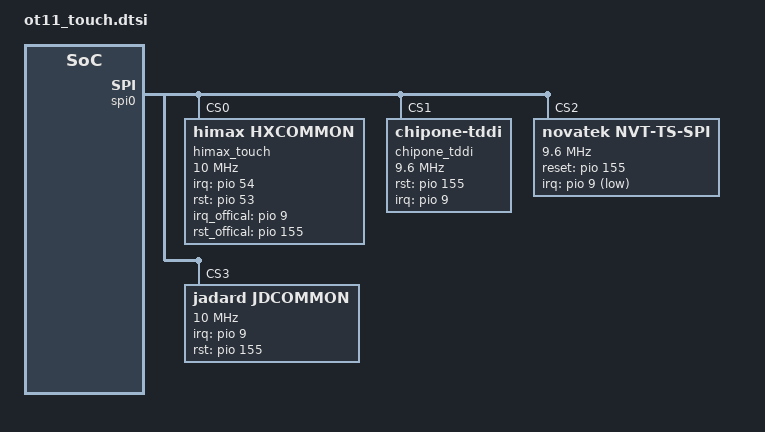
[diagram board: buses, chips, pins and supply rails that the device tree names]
// SPDX-License-Identifier: (GPL-2.0 OR MIT)
/*
 * Copyright (C) 2020 MediaTek Inc.
 */

/* TOUCH start */
&spi0 {
    status = "okay";
    #address-cells = <1>;
    #size-cells = <0>;
    mediatek,pad-select = <0>;
    /*Tab A9 code for AX6739W-7 by xiongwei at 20250812 start*/
    cs-gpios = <0>, <0>, <0>, <0>;
    /*Tab A9 code for AX6739W-7 by xiongwei at 20250812 end*/

    himax_touch@0 {
        compatible = "himax,hxcommon";
        reg = <0>;
        status = "okay";
        spi-max-frequency = <10000000>;
        spi-cpha;
        interrupt-parent = <&pio>;
        himax,panel-coords = <0 800 0 1340>;
        himax,display-coords = <0 800 0 1340>;
        himax,irq-gpio = <&pio 54 0x00>;
	/*Tab A9 code for AX6739W-46 by xiongwei at 20250827 start*/
        himax,rst-gpio = <&pio 53 0x00>;
	/*Tab A9 code for AX6739W-46 by xiongwei at 20250827 end*/

        himax,irq_offical-gpio = <&pio 9 0x00>;
        himax,rst_offical-gpio = <&pio 155 0x00>;
        report_type = <1>;
    };
    chipone_tddi@1 {
        compatible = "chipone-tddi";
        reg = <1>;
        spi-max-frequency = <9600000>;
        interrupt-parent = <&pio>;
        interrupts = <9 0x2008>;
        chipone,rst-gpio = <&pio 155 0x00>;
        chipone,irq-gpio = <&pio 9 0x00>;
        //chipone,cs-gpio = <&pio 8 0>;
        chipone,x-res = <800>;
        chipone,y-res = <1340>;

        /* Charger detect */
        chipone,touch-charger-detect-enable;
        chipone,touch-charger-detect-type = "notify"; /* notify, poll */
        chipone,touch-charger-detect-psy-name = "charger";
        chipone,touch-charger-detect-psp = "POWER_SUPPLY_PROP_ONLINE";
        chipone,touch-charger-detect-psp-poll-interval = <1000>;

        /* Earjack detect */
        chipone,touch-earjack-detect-enable;
        /* MTK:  /sys/bus/platform/drivers/Accdet_Driver/state,
           Sprd: /sys/kernel/headset/state
           QCOM: None, and disable it */
        chipone,touch-earjack-state-filepath = "/sys/bus/platform/drivers/Accdet_Driver/state";
        chipone,touch-earjack-poll-interval = <1000>;

        /* For tp selftest */
        chipone,test-reset-pin;
        //chipone,test-int-pin;
        chipone,test-rawdata;
        chipone,test-rawdata-frames      = <1>;
        chipone,rawdata-min              = <100>;
        chipone,rawdata-max              = <10000>;
        chipone,test-noise;
        chipone,test-noise-frames        = <50>;
        chipone,noise-max                = <1000>;
        chipone,test-open;
        chipone,open-min                 = <200>;
        chipone,test-short;
        chipone,short-min                = <200>;
        chipone,test-compensate-cap;
        chipone,compensate-cap-min       = <1>;
        chipone,compensate-cap-max       = <127>;

    };
    /* Novatek device tree node */
    novatek@2 {
        compatible = "novatek,NVT-ts-spi";
        reg = <2>; //Same as CS ID
        status = "ok";

        spi-max-frequency = <9600000>;    //4800000,9600000,15000000,19200000
        novatek,reset-gpio = <&pio 155 0x00>;
        novatek,irq-gpio = <&pio 9 0x2001>;

        /* 525 */
        //novatek,swrst-n8-addr = <0x01F01A>;

        /* 672A, 525B, 675, 526, 672C, 523, 528, 523D */
        novatek,swrst-n8-addr = <0x03F0FE>;
        novatek,spi-rd-fast-addr = <0x03F310>;

        /*Panel setting*/
        novatek,resolution = <800 1340>;
        novatek,max_touch_num = <10>;
        novatek,area-size = <56 112 60>;    //indicator navigation edge
        novatek,fw_name = "novatek_ts_fw.bin", "tsp_novatek/OT11_NT36523D_LC_HSD_FW_V001_2023xxxx.bin";
        novatek,fw_name_mp = "novatek_ts_mp.bin", "tsp_novatek/OT11_NT36523D_LC_HSD_MP_V001_2023xxxx.bin ";
        //novatek,support_ear_detect_mode;
        novatek,enable_settings_aot;

        /* MP */
        novatek,mp-support-dt;

        novatek-mp-criteria-725E@0 {
            #address-cells = <1>;
            #size-cells = <0>;
            compatible = "novatek-mp-criteria-725E";

            /* sec cmd test config */
            open_test_spec = <(-511) 5120>;
            short_test_spec = <10000 14008>;
            diff_test_frame = <50>;
            /* sec cmd fdm test config */
            fdm_x_num = <2>;
            fdm_diff_test_frame = <50>;

            /* MP Config */
            IC_X_CFG_SIZE = <22>;
            IC_Y_CFG_SIZE = <36>;
            IC_KEY_CFG_SIZE = <4>;
            X_Channel = <22>;
            Y_Channel = <36>;
            AIN_X = <0 1 2 3 4 5 6 7 8 9 10 11 12 13 14 15 16 17 18 19 20 21>; // 22 23 24 25 26 27 28 29 30 31>;
            AIN_Y = <0 1 2 3 4 5 6 7 8 9 10 11 12 13 14 15 16 17
                        18 19 20 21 22 23 24 25 26 27 28 29 30 31 32 33 34 35>; // 36 37 38 39
                        //40 41 42 43 44 45 46 47 48 49>;
            AIN_KEY = <0 1 2 0xFF 0xFF 0xFF 0xFF 0xFF>;

            /* MP Criteria */
            PS_Config_Lmt_Short_Rawdata_P = <
                14008 14008 14008 14008 14008 14008 14008 14008 14008 14008 14008 14008 14008 14008 14008 14008 14008 14008 14008 14008 14008 14008
                14008 14008 14008 14008 14008 14008 14008 14008 14008 14008 14008 14008 14008 14008 14008 14008 14008 14008 14008 14008 14008 14008
                14008 14008 14008 14008 14008 14008 14008 14008 14008 14008 14008 14008 14008 14008 14008 14008 14008 14008 14008 14008 14008 14008
                14008 14008 14008 14008 14008 14008 14008 14008 14008 14008 14008 14008 14008 14008 14008 14008 14008 14008 14008 14008 14008 14008
                14008 14008 14008 14008 14008 14008 14008 14008 14008 14008 14008 14008 14008 14008 14008 14008 14008 14008 14008 14008 14008 14008
                14008 14008 14008 14008 14008 14008 14008 14008 14008 14008 14008 14008 14008 14008 14008 14008 14008 14008 14008 14008 14008 14008
                14008 14008 14008 14008 14008 14008 14008 14008 14008 14008 14008 14008 14008 14008 14008 14008 14008 14008 14008 14008 14008 14008
                14008 14008 14008 14008 14008 14008 14008 14008 14008 14008 14008 14008 14008 14008 14008 14008 14008 14008 14008 14008 14008 14008
                14008 14008 14008 14008 14008 14008 14008 14008 14008 14008 14008 14008 14008 14008 14008 14008 14008 14008 14008 14008 14008 14008
                14008 14008 14008 14008 14008 14008 14008 14008 14008 14008 14008 14008 14008 14008 14008 14008 14008 14008 14008 14008 14008 14008
                14008 14008 14008 14008 14008 14008 14008 14008 14008 14008 14008 14008 14008 14008 14008 14008 14008 14008 14008 14008 14008 14008
                14008 14008 14008 14008 14008 14008 14008 14008 14008 14008 14008 14008 14008 14008 14008 14008 14008 14008 14008 14008 14008 14008
                14008 14008 14008 14008 14008 14008 14008 14008 14008 14008 14008 14008 14008 14008 14008 14008 14008 14008 14008 14008 14008 14008
                14008 14008 14008 14008 14008 14008 14008 14008 14008 14008 14008 14008 14008 14008 14008 14008 14008 14008 14008 14008 14008 14008
                14008 14008 14008 14008 14008 14008 14008 14008 14008 14008 14008 14008 14008 14008 14008 14008 14008 14008 14008 14008 14008 14008
                14008 14008 14008 14008 14008 14008 14008 14008 14008 14008 14008 14008 14008 14008 14008 14008 14008 14008 14008 14008 14008 14008
                14008 14008 14008 14008 14008 14008 14008 14008 14008 14008 14008 14008 14008 14008 14008 14008 14008 14008 14008 14008 14008 14008
                14008 14008 14008 14008 14008 14008 14008 14008 14008 14008 14008 14008 14008 14008 14008 14008 14008 14008 14008 14008 14008 14008
                14008 14008 14008 14008 14008 14008 14008 14008 14008 14008 14008 14008 14008 14008 14008 14008 14008 14008 14008 14008 14008 14008
                14008 14008 14008 14008 14008 14008 14008 14008 14008 14008 14008 14008 14008 14008 14008 14008 14008 14008 14008 14008 14008 14008
                14008 14008 14008 14008 14008 14008 14008 14008 14008 14008 14008 14008 14008 14008 14008 14008 14008 14008 14008 14008 14008 14008
                14008 14008 14008 14008 14008 14008 14008 14008 14008 14008 14008 14008 14008 14008 14008 14008 14008 14008 14008 14008 14008 14008
                14008 14008 14008 14008 14008 14008 14008 14008 14008 14008 14008 14008 14008 14008 14008 14008 14008 14008 14008 14008 14008 14008
                14008 14008 14008 14008 14008 14008 14008 14008 14008 14008 14008 14008 14008 14008 14008 14008 14008 14008 14008 14008 14008 14008
                14008 14008 14008 14008 14008 14008 14008 14008 14008 14008 14008 14008 14008 14008 14008 14008 14008 14008 14008 14008 14008 14008
                14008 14008 14008 14008 14008 14008 14008 14008 14008 14008 14008 14008 14008 14008 14008 14008 14008 14008 14008 14008 14008 14008
                14008 14008 14008 14008 14008 14008 14008 14008 14008 14008 14008 14008 14008 14008 14008 14008 14008 14008 14008 14008 14008 14008
                14008 14008 14008 14008 14008 14008 14008 14008 14008 14008 14008 14008 14008 14008 14008 14008 14008 14008 14008 14008 14008 14008
                14008 14008 14008 14008 14008 14008 14008 14008 14008 14008 14008 14008 14008 14008 14008 14008 14008 14008 14008 14008 14008 14008
                14008 14008 14008 14008 14008 14008 14008 14008 14008 14008 14008 14008 14008 14008 14008 14008 14008 14008 14008 14008 14008 14008
                14008 14008 14008 14008 14008 14008 14008 14008 14008 14008 14008 14008 14008 14008 14008 14008 14008 14008 14008 14008 14008 14008
                14008 14008 14008 14008 14008 14008 14008 14008 14008 14008 14008 14008 14008 14008 14008 14008 14008 14008 14008 14008 14008 14008
                14008 14008 14008 14008 14008 14008 14008 14008 14008 14008 14008 14008 14008 14008 14008 14008 14008 14008 14008 14008 14008 14008
                14008 14008 14008 14008 14008 14008 14008 14008 14008 14008 14008 14008 14008 14008 14008 14008 14008 14008 14008 14008 14008 14008
                14008 14008 14008 14008 14008 14008 14008 14008 14008 14008 14008 14008 14008 14008 14008 14008 14008 14008 14008 14008 14008 14008
                14008 14008 14008 14008 14008 14008 14008 14008 14008 14008 14008 14008 14008 14008 14008 14008 14008 14008 14008 14008 14008 14008
                14008 14008 14008>;

            PS_Config_Lmt_Short_Rawdata_N = <
                10000 10000 10000 10000 10000 10000 10000 10000 10000 10000 10000 10000 10000 10000 10000 10000 10000 10000 10000 10000 10000 10000
                10000 10000 10000 10000 10000 10000 10000 10000 10000 10000 10000 10000 10000 10000 10000 10000 10000 10000 10000 10000 10000 10000
                10000 10000 10000 10000 10000 10000 10000 10000 10000 10000 10000 10000 10000 10000 10000 10000 10000 10000 10000 10000 10000 10000
                10000 10000 10000 10000 10000 10000 10000 10000 10000 10000 10000 10000 10000 10000 10000 10000 10000 10000 10000 10000 10000 10000
                10000 10000 10000 10000 10000 10000 10000 10000 10000 10000 10000 10000 10000 10000 10000 10000 10000 10000 10000 10000 10000 10000
                10000 10000 10000 10000 10000 10000 10000 10000 10000 10000 10000 10000 10000 10000 10000 10000 10000 10000 10000 10000 10000 10000
                10000 10000 10000 10000 10000 10000 10000 10000 10000 10000 10000 10000 10000 10000 10000 10000 10000 10000 10000 10000 10000 10000
                10000 10000 10000 10000 10000 10000 10000 10000 10000 10000 10000 10000 10000 10000 10000 10000 10000 10000 10000 10000 10000 10000
                10000 10000 10000 10000 10000 10000 10000 10000 10000 10000 10000 10000 10000 10000 10000 10000 10000 10000 10000 10000 10000 10000
                10000 10000 10000 10000 10000 10000 10000 10000 10000 10000 10000 10000 10000 10000 10000 10000 10000 10000 10000 10000 10000 10000
                10000 10000 10000 10000 10000 10000 10000 10000 10000 10000 10000 10000 10000 10000 10000 10000 10000 10000 10000 10000 10000 10000
                10000 10000 10000 10000 10000 10000 10000 10000 10000 10000 10000 10000 10000 10000 10000 10000 10000 10000 10000 10000 10000 10000
                10000 10000 10000 10000 10000 10000 10000 10000 10000 10000 10000 10000 10000 10000 10000 10000 10000 10000 10000 10000 10000 10000
                10000 10000 10000 10000 10000 10000 10000 10000 10000 10000 10000 10000 10000 10000 10000 10000 10000 10000 10000 10000 10000 10000
                10000 10000 10000 10000 10000 10000 10000 10000 10000 10000 10000 10000 10000 10000 10000 10000 10000 10000 10000 10000 10000 10000
                10000 10000 10000 10000 10000 10000 10000 10000 10000 10000 10000 10000 10000 10000 10000 10000 10000 10000 10000 10000 10000 10000
                10000 10000 10000 10000 10000 10000 10000 10000 10000 10000 10000 10000 10000 10000 10000 10000 10000 10000 10000 10000 10000 10000
                10000 10000 10000 10000 10000 10000 10000 10000 10000 10000 10000 10000 10000 10000 10000 10000 10000 10000 10000 10000 10000 10000
                10000 10000 10000 10000 10000 10000 10000 10000 10000 10000 10000 10000 10000 10000 10000 10000 10000 10000 10000 10000 10000 10000
                10000 10000 10000 10000 10000 10000 10000 10000 10000 10000 10000 10000 10000 10000 10000 10000 10000 10000 10000 10000 10000 10000
                10000 10000 10000 10000 10000 10000 10000 10000 10000 10000 10000 10000 10000 10000 10000 10000 10000 10000 10000 10000 10000 10000
                10000 10000 10000 10000 10000 10000 10000 10000 10000 10000 10000 10000 10000 10000 10000 10000 10000 10000 10000 10000 10000 10000
                10000 10000 10000 10000 10000 10000 10000 10000 10000 10000 10000 10000 10000 10000 10000 10000 10000 10000 10000 10000 10000 10000
                10000 10000 10000 10000 10000 10000 10000 10000 10000 10000 10000 10000 10000 10000 10000 10000 10000 10000 10000 10000 10000 10000
                10000 10000 10000 10000 10000 10000 10000 10000 10000 10000 10000 10000 10000 10000 10000 10000 10000 10000 10000 10000 10000 10000
                10000 10000 10000 10000 10000 10000 10000 10000 10000 10000 10000 10000 10000 10000 10000 10000 10000 10000 10000 10000 10000 10000
                10000 10000 10000 10000 10000 10000 10000 10000 10000 10000 10000 10000 10000 10000 10000 10000 10000 10000 10000 10000 10000 10000
                10000 10000 10000 10000 10000 10000 10000 10000 10000 10000 10000 10000 10000 10000 10000 10000 10000 10000 10000 10000 10000 10000
                10000 10000 10000 10000 10000 10000 10000 10000 10000 10000 10000 10000 10000 10000 10000 10000 10000 10000 10000 10000 10000 10000
                10000 10000 10000 10000 10000 10000 10000 10000 10000 10000 10000 10000 10000 10000 10000 10000 10000 10000 10000 10000 10000 10000
                10000 10000 10000 10000 10000 10000 10000 10000 10000 10000 10000 10000 10000 10000 10000 10000 10000 10000 10000 10000 10000 10000
                10000 10000 10000 10000 10000 10000 10000 10000 10000 10000 10000 10000 10000 10000 10000 10000 10000 10000 10000 10000 10000 10000
                10000 10000 10000 10000 10000 10000 10000 10000 10000 10000 10000 10000 10000 10000 10000 10000 10000 10000 10000 10000 10000 10000
                10000 10000 10000 10000 10000 10000 10000 10000 10000 10000 10000 10000 10000 10000 10000 10000 10000 10000 10000 10000 10000 10000
                10000 10000 10000 10000 10000 10000 10000 10000 10000 10000 10000 10000 10000 10000 10000 10000 10000 10000 10000 10000 10000 10000
                10000 10000 10000 10000 10000 10000 10000 10000 10000 10000 10000 10000 10000 10000 10000 10000 10000 10000 10000 10000 10000 10000
                10000 10000 10000>;

            PS_Config_Lmt_Open_Rawdata_P = <
                5120 5120 5120 5120 5120 5120 5120 5120 5120 5120 5120 5120 5120 5120 5120 5120 5120 5120 5120 5120 5120 5120
                5120 5120 5120 5120 5120 5120 5120 5120 5120 5120 5120 5120 5120 5120 5120 5120 5120 5120 5120 5120 5120 5120
                5120 5120 5120 5120 5120 5120 5120 5120 5120 5120 5120 5120 5120 5120 5120 5120 5120 5120 5120 5120 5120 5120
                5120 5120 5120 5120 5120 5120 5120 5120 5120 5120 5120 5120 5120 5120 5120 5120 5120 5120 5120 5120 5120 5120
                5120 5120 5120 5120 5120 5120 5120 5120 5120 5120 5120 5120 5120 5120 5120 5120 5120 5120 5120 5120 5120 5120
                5120 5120 5120 5120 5120 5120 5120 5120 5120 5120 5120 5120 5120 5120 5120 5120 5120 5120 5120 5120 5120 5120
                5120 5120 5120 5120 5120 5120 5120 5120 5120 5120 5120 5120 5120 5120 5120 5120 5120 5120 5120 5120 5120 5120
                5120 5120 5120 5120 5120 5120 5120 5120 5120 5120 5120 5120 5120 5120 5120 5120 5120 5120 5120 5120 5120 5120
                5120 5120 5120 5120 5120 5120 5120 5120 5120 5120 5120 5120 5120 5120 5120 5120 5120 5120 5120 5120 5120 5120
                5120 5120 5120 5120 5120 5120 5120 5120 5120 5120 5120 5120 5120 5120 5120 5120 5120 5120 5120 5120 5120 5120
                5120 5120 5120 5120 5120 5120 5120 5120 5120 5120 5120 5120 5120 5120 5120 5120 5120 5120 5120 5120 5120 5120
                5120 5120 5120 5120 5120 5120 5120 5120 5120 5120 5120 5120 5120 5120 5120 5120 5120 5120 5120 5120 5120 5120
                5120 5120 5120 5120 5120 5120 5120 5120 5120 5120 5120 5120 5120 5120 5120 5120 5120 5120 5120 5120 5120 5120
                5120 5120 5120 5120 5120 5120 5120 5120 5120 5120 5120 5120 5120 5120 5120 5120 5120 5120 5120 5120 5120 5120
                5120 5120 5120 5120 5120 5120 5120 5120 5120 5120 5120 5120 5120 5120 5120 5120 5120 5120 5120 5120 5120 5120
                5120 5120 5120 5120 5120 5120 5120 5120 5120 5120 5120 5120 5120 5120 5120 5120 5120 5120 5120 5120 5120 5120
                5120 5120 5120 5120 5120 5120 5120 5120 5120 5120 5120 5120 5120 5120 5120 5120 5120 5120 5120 5120 5120 5120
                5120 5120 5120 5120 5120 5120 5120 5120 5120 5120 5120 5120 5120 5120 5120 5120 5120 5120 5120 5120 5120 5120
                5120 5120 5120 5120 5120 5120 5120 5120 5120 5120 5120 5120 5120 5120 5120 5120 5120 5120 5120 5120 5120 5120
                5120 5120 5120 5120 5120 5120 5120 5120 5120 5120 5120 5120 5120 5120 5120 5120 5120 5120 5120 5120 5120 5120
                5120 5120 5120 5120 5120 5120 5120 5120 5120 5120 5120 5120 5120 5120 5120 5120 5120 5120 5120 5120 5120 5120
                5120 5120 5120 5120 5120 5120 5120 5120 5120 5120 5120 5120 5120 5120 5120 5120 5120 5120 5120 5120 5120 5120
                5120 5120 5120 5120 5120 5120 5120 5120 5120 5120 5120 5120 5120 5120 5120 5120 5120 5120 5120 5120 5120 5120
                5120 5120 5120 5120 5120 5120 5120 5120 5120 5120 5120 5120 5120 5120 5120 5120 5120 5120 5120 5120 5120 5120
                5120 5120 5120 5120 5120 5120 5120 5120 5120 5120 5120 5120 5120 5120 5120 5120 5120 5120 5120 5120 5120 5120
                5120 5120 5120 5120 5120 5120 5120 5120 5120 5120 5120 5120 5120 5120 5120 5120 5120 5120 5120 5120 5120 5120
                5120 5120 5120 5120 5120 5120 5120 5120 5120 5120 5120 5120 5120 5120 5120 5120 5120 5120 5120 5120 5120 5120
                5120 5120 5120 5120 5120 5120 5120 5120 5120 5120 5120 5120 5120 5120 5120 5120 5120 5120 5120 5120 5120 5120
                5120 5120 5120 5120 5120 5120 5120 5120 5120 5120 5120 5120 5120 5120 5120 5120 5120 5120 5120 5120 5120 5120
                5120 5120 5120 5120 5120 5120 5120 5120 5120 5120 5120 5120 5120 5120 5120 5120 5120 5120 5120 5120 5120 5120
                5120 5120 5120 5120 5120 5120 5120 5120 5120 5120 5120 5120 5120 5120 5120 5120 5120 5120 5120 5120 5120 5120
                5120 5120 5120 5120 5120 5120 5120 5120 5120 5120 5120 5120 5120 5120 5120 5120 5120 5120 5120 5120 5120 5120
                5120 5120 5120 5120 5120 5120 5120 5120 5120 5120 5120 5120 5120 5120 5120 5120 5120 5120 5120 5120 5120 5120
                5120 5120 5120 5120 5120 5120 5120 5120 5120 5120 5120 5120 5120 5120 5120 5120 5120 5120 5120 5120 5120 5120
                5120 5120 5120 5120 5120 5120 5120 5120 5120 5120 5120 5120 5120 5120 5120 5120 5120 5120 5120 5120 5120 5120
                5120 5120 5120 5120 5120 5120 5120 5120 5120 5120 5120 5120 5120 5120 5120 5120 5120 5120 5120 5120 5120 5120
                5120 5120 5120>;

            PS_Config_Lmt_Open_Rawdata_N = <
                (-511) (-511) (-511) (-511) (-511) (-511) (-511) (-511) (-511) (-511) (-511) (-511) (-511) (-511) (-511) (-511) (-511) (-511) (-511) (-511) (-511) (-511)
                (-511) (-511) (-511) (-511) (-511) (-511) (-511) (-511) (-511) (-511) (-511) (-511) (-511) (-511) (-511) (-511) (-511) (-511) (-511) (-511) (-511) (-511)
                (-511) (-511) (-511) (-511) (-511) (-511) (-511) (-511) (-511) (-511) (-511) (-511) (-511) (-511) (-511) (-511) (-511) (-511) (-511) (-511) (-511) (-511)
                (-511) (-511) (-511) (-511) (-511) (-511) (-511) (-511) (-511) (-511) (-511) (-511) (-511) (-511) (-511) (-511) (-511) (-511) (-511) (-511) (-511) (-511)
                (-511) (-511) (-511) (-511) (-511) (-511) (-511) (-511) (-511) (-511) (-511) (-511) (-511) (-511) (-511) (-511) (-511) (-511) (-511) (-511) (-511) (-511)
                (-511) (-511) (-511) (-511) (-511) (-511) (-511) (-511) (-511) (-511) (-511) (-511) (-511) (-511) (-511) (-511) (-511) (-511) (-511) (-511) (-511) (-511)
                (-511) (-511) (-511) (-511) (-511) (-511) (-511) (-511) (-511) (-511) (-511) (-511) (-511) (-511) (-511) (-511) (-511) (-511) (-511) (-511) (-511) (-511)
                (-511) (-511) (-511) (-511) (-511) (-511) (-511) (-511) (-511) (-511) (-511) (-511) (-511) (-511) (-511) (-511) (-511) (-511) (-511) (-511) (-511) (-511)
                (-511) (-511) (-511) (-511) (-511) (-511) (-511) (-511) (-511) (-511) (-511) (-511) (-511) (-511) (-511) (-511) (-511) (-511) (-511) (-511) (-511) (-511)
                (-511) (-511) (-511) (-511) (-511) (-511) (-511) (-511) (-511) (-511) (-511) (-511) (-511) (-511) (-511) (-511) (-511) (-511) (-511) (-511) (-511) (-511)
                (-511) (-511) (-511) (-511) (-511) (-511) (-511) (-511) (-511) (-511) (-511) (-511) (-511) (-511) (-511) (-511) (-511) (-511) (-511) (-511) (-511) (-511)
                (-511) (-511) (-511) (-511) (-511) (-511) (-511) (-511) (-511) (-511) (-511) (-511) (-511) (-511) (-511) (-511) (-511) (-511) (-511) (-511) (-511) (-511)
                (-511) (-511) (-511) (-511) (-511) (-511) (-511) (-511) (-511) (-511) (-511) (-511) (-511) (-511) (-511) (-511) (-511) (-511) (-511) (-511) (-511) (-511)
                (-511) (-511) (-511) (-511) (-511) (-511) (-511) (-511) (-511) (-511) (-511) (-511) (-511) (-511) (-511) (-511) (-511) (-511) (-511) (-511) (-511) (-511)
                (-511) (-511) (-511) (-511) (-511) (-511) (-511) (-511) (-511) (-511) (-511) (-511) (-511) (-511) (-511) (-511) (-511) (-511) (-511) (-511) (-511) (-511)
                (-511) (-511) (-511) (-511) (-511) (-511) (-511) (-511) (-511) (-511) (-511) (-511) (-511) (-511) (-511) (-511) (-511) (-511) (-511) (-511) (-511) (-511)
                (-511) (-511) (-511) (-511) (-511) (-511) (-511) (-511) (-511) (-511) (-511) (-511) (-511) (-511) (-511) (-511) (-511) (-511) (-511) (-511) (-511) (-511)
                (-511) (-511) (-511) (-511) (-511) (-511) (-511) (-511) (-511) (-511) (-511) (-511) (-511) (-511) (-511) (-511) (-511) (-511) (-511) (-511) (-511) (-511)
                (-511) (-511) (-511) (-511) (-511) (-511) (-511) (-511) (-511) (-511) (-511) (-511) (-511) (-511) (-511) (-511) (-511) (-511) (-511) (-511) (-511) (-511)
                (-511) (-511) (-511) (-511) (-511) (-511) (-511) (-511) (-511) (-511) (-511) (-511) (-511) (-511) (-511) (-511) (-511) (-511) (-511) (-511) (-511) (-511)
                (-511) (-511) (-511) (-511) (-511) (-511) (-511) (-511) (-511) (-511) (-511) (-511) (-511) (-511) (-511) (-511) (-511) (-511) (-511) (-511) (-511) (-511)
                (-511) (-511) (-511) (-511) (-511) (-511) (-511) (-511) (-511) (-511) (-511) (-511) (-511) (-511) (-511) (-511) (-511) (-511) (-511) (-511) (-511) (-511)
                (-511) (-511) (-511) (-511) (-511) (-511) (-511) (-511) (-511) (-511) (-511) (-511) (-511) (-511) (-511) (-511) (-511) (-511) (-511) (-511) (-511) (-511)
                (-511) (-511) (-511) (-511) (-511) (-511) (-511) (-511) (-511) (-511) (-511) (-511) (-511) (-511) (-511) (-511) (-511) (-511) (-511) (-511) (-511) (-511)
                (-511) (-511) (-511) (-511) (-511) (-511) (-511) (-511) (-511) (-511) (-511) (-511) (-511) (-511) (-511) (-511) (-511) (-511) (-511) (-511) (-511) (-511)
                (-511) (-511) (-511) (-511) (-511) (-511) (-511) (-511) (-511) (-511) (-511) (-511) (-511) (-511) (-511) (-511) (-511) (-511) (-511) (-511) (-511) (-511)
                (-511) (-511) (-511) (-511) (-511) (-511) (-511) (-511) (-511) (-511) (-511) (-511) (-511) (-511) (-511) (-511) (-511) (-511) (-511) (-511) (-511) (-511)
                (-511) (-511) (-511) (-511) (-511) (-511) (-511) (-511) (-511) (-511) (-511) (-511) (-511) (-511) (-511) (-511) (-511) (-511) (-511) (-511) (-511) (-511)
                (-511) (-511) (-511) (-511) (-511) (-511) (-511) (-511) (-511) (-511) (-511) (-511) (-511) (-511) (-511) (-511) (-511) (-511) (-511) (-511) (-511) (-511)
                (-511) (-511) (-511) (-511) (-511) (-511) (-511) (-511) (-511) (-511) (-511) (-511) (-511) (-511) (-511) (-511) (-511) (-511) (-511) (-511) (-511) (-511)
                (-511) (-511) (-511) (-511) (-511) (-511) (-511) (-511) (-511) (-511) (-511) (-511) (-511) (-511) (-511) (-511) (-511) (-511) (-511) (-511) (-511) (-511)
                (-511) (-511) (-511) (-511) (-511) (-511) (-511) (-511) (-511) (-511) (-511) (-511) (-511) (-511) (-511) (-511) (-511) (-511) (-511) (-511) (-511) (-511)
                (-511) (-511) (-511) (-511) (-511) (-511) (-511) (-511) (-511) (-511) (-511) (-511) (-511) (-511) (-511) (-511) (-511) (-511) (-511) (-511) (-511) (-511)
                (-511) (-511) (-511) (-511) (-511) (-511) (-511) (-511) (-511) (-511) (-511) (-511) (-511) (-511) (-511) (-511) (-511) (-511) (-511) (-511) (-511) (-511)
                (-511) (-511) (-511) (-511) (-511) (-511) (-511) (-511) (-511) (-511) (-511) (-511) (-511) (-511) (-511) (-511) (-511) (-511) (-511) (-511) (-511) (-511)
                (-511) (-511) (-511) (-511) (-511) (-511) (-511) (-511) (-511) (-511) (-511) (-511) (-511) (-511) (-511) (-511) (-511) (-511) (-511) (-511) (-511) (-511)
                (-511) (-511) (-511)>;

            PS_Config_Lmt_FW_Rawdata_P = <
                3840 3840 3840 3840 3840 3840 3840 3840 3840 3840 3840 3840 3840 3840 3840 3840 3840 3840 3840 3840 3840 3840
                3840 3840 3840 3840 3840 3840 3840 3840 3840 3840 3840 3840 3840 3840 3840 3840 3840 3840 3840 3840 3840 3840
                3840 3840 3840 3840 3840 3840 3840 3840 3840 3840 3840 3840 3840 3840 3840 3840 3840 3840 3840 3840 3840 3840
                3840 3840 3840 3840 3840 3840 3840 3840 3840 3840 3840 3840 3840 3840 3840 3840 3840 3840 3840 3840 3840 3840
                3840 3840 3840 3840 3840 3840 3840 3840 3840 3840 3840 3840 3840 3840 3840 3840 3840 3840 3840 3840 3840 3840
                3840 3840 3840 3840 3840 3840 3840 3840 3840 3840 3840 3840 3840 3840 3840 3840 3840 3840 3840 3840 3840 3840
                3840 3840 3840 3840 3840 3840 3840 3840 3840 3840 3840 3840 3840 3840 3840 3840 3840 3840 3840 3840 3840 3840
                3840 3840 3840 3840 3840 3840 3840 3840 3840 3840 3840 3840 3840 3840 3840 3840 3840 3840 3840 3840 3840 3840
                3840 3840 3840 3840 3840 3840 3840 3840 3840 3840 3840 3840 3840 3840 3840 3840 3840 3840 3840 3840 3840 3840
                3840 3840 3840 3840 3840 3840 3840 3840 3840 3840 3840 3840 3840 3840 3840 3840 3840 3840 3840 3840 3840 3840
                3840 3840 3840 3840 3840 3840 3840 3840 3840 3840 3840 3840 3840 3840 3840 3840 3840 3840 3840 3840 3840 3840
                3840 3840 3840 3840 3840 3840 3840 3840 3840 3840 3840 3840 3840 3840 3840 3840 3840 3840 3840 3840 3840 3840
                3840 3840 3840 3840 3840 3840 3840 3840 3840 3840 3840 3840 3840 3840 3840 3840 3840 3840 3840 3840 3840 3840
                3840 3840 3840 3840 3840 3840 3840 3840 3840 3840 3840 3840 3840 3840 3840 3840 3840 3840 3840 3840 3840 3840
                3840 3840 3840 3840 3840 3840 3840 3840 3840 3840 3840 3840 3840 3840 3840 3840 3840 3840 3840 3840 3840 3840
                3840 3840 3840 3840 3840 3840 3840 3840 3840 3840 3840 3840 3840 3840 3840 3840 3840 3840 3840 3840 3840 3840
                3840 3840 3840 3840 3840 3840 3840 3840 3840 3840 3840 3840 3840 3840 3840 3840 3840 3840 3840 3840 3840 3840
                3840 3840 3840 3840 3840 3840 3840 3840 3840 3840 3840 3840 3840 3840 3840 3840 3840 3840 3840 3840 3840 3840
                3840 3840 3840 3840 3840 3840 3840 3840 3840 3840 3840 3840 3840 3840 3840 3840 3840 3840 3840 3840 3840 3840
                3840 3840 3840 3840 3840 3840 3840 3840 3840 3840 3840 3840 3840 3840 3840 3840 3840 3840 3840 3840 3840 3840
                3840 3840 3840 3840 3840 3840 3840 3840 3840 3840 3840 3840 3840 3840 3840 3840 3840 3840 3840 3840 3840 3840
                3840 3840 3840 3840 3840 3840 3840 3840 3840 3840 3840 3840 3840 3840 3840 3840 3840 3840 3840 3840 3840 3840
                3840 3840 3840 3840 3840 3840 3840 3840 3840 3840 3840 3840 3840 3840 3840 3840 3840 3840 3840 3840 3840 3840
                3840 3840 3840 3840 3840 3840 3840 3840 3840 3840 3840 3840 3840 3840 3840 3840 3840 3840 3840 3840 3840 3840
                3840 3840 3840 3840 3840 3840 3840 3840 3840 3840 3840 3840 3840 3840 3840 3840 3840 3840 3840 3840 3840 3840
                3840 3840 3840 3840 3840 3840 3840 3840 3840 3840 3840 3840 3840 3840 3840 3840 3840 3840 3840 3840 3840 3840
                3840 3840 3840 3840 3840 3840 3840 3840 3840 3840 3840 3840 3840 3840 3840 3840 3840 3840 3840 3840 3840 3840
                3840 3840 3840 3840 3840 3840 3840 3840 3840 3840 3840 3840 3840 3840 3840 3840 3840 3840 3840 3840 3840 3840
                3840 3840 3840 3840 3840 3840 3840 3840 3840 3840 3840 3840 3840 3840 3840 3840 3840 3840 3840 3840 3840 3840
                3840 3840 3840 3840 3840 3840 3840 3840 3840 3840 3840 3840 3840 3840 3840 3840 3840 3840 3840 3840 3840 3840
                3840 3840 3840 3840 3840 3840 3840 3840 3840 3840 3840 3840 3840 3840 3840 3840 3840 3840 3840 3840 3840 3840
                3840 3840 3840 3840 3840 3840 3840 3840 3840 3840 3840 3840 3840 3840 3840 3840 3840 3840 3840 3840 3840 3840
                3840 3840 3840 3840 3840 3840 3840 3840 3840 3840 3840 3840 3840 3840 3840 3840 3840 3840 3840 3840 3840 3840
                3840 3840 3840 3840 3840 3840 3840 3840 3840 3840 3840 3840 3840 3840 3840 3840 3840 3840 3840 3840 3840 3840
                3840 3840 3840 3840 3840 3840 3840 3840 3840 3840 3840 3840 3840 3840 3840 3840 3840 3840 3840 3840 3840 3840
                3840 3840 3840 3840 3840 3840 3840 3840 3840 3840 3840 3840 3840 3840 3840 3840 3840 3840 3840 3840 3840 3840
                3840 3840 3840>;

            PS_Config_Lmt_FW_Rawdata_N = <
                240 240 240 240 240 240 240 240 240 240 240 240 240 240 240 240 240 240 240 240 240 240
                240 240 240 240 240 240 240 240 240 240 240 240 240 240 240 240 240 240 240 240 240 240
                240 240 240 240 240 240 240 240 240 240 240 240 240 240 240 240 240 240 240 240 240 240
                240 240 240 240 240 240 240 240 240 240 240 240 240 240 240 240 240 240 240 240 240 240
                240 240 240 240 240 240 240 240 240 240 240 240 240 240 240 240 240 240 240 240 240 240
                240 240 240 240 240 240 240 240 240 240 240 240 240 240 240 240 240 240 240 240 240 240
                240 240 240 240 240 240 240 240 240 240 240 240 240 240 240 240 240 240 240 240 240 240
                240 240 240 240 240 240 240 240 240 240 240 240 240 240 240 240 240 240 240 240 240 240
                240 240 240 240 240 240 240 240 240 240 240 240 240 240 240 240 240 240 240 240 240 240
                240 240 240 240 240 240 240 240 240 240 240 240 240 240 240 240 240 240 240 240 240 240
                240 240 240 240 240 240 240 240 240 240 240 240 240 240 240 240 240 240 240 240 240 240
                240 240 240 240 240 240 240 240 240 240 240 240 240 240 240 240 240 240 240 240 240 240
                240 240 240 240 240 240 240 240 240 240 240 240 240 240 240 240 240 240 240 240 240 240
                240 240 240 240 240 240 240 240 240 240 240 240 240 240 240 240 240 240 240 240 240 240
                240 240 240 240 240 240 240 240 240 240 240 240 240 240 240 240 240 240 240 240 240 240
                240 240 240 240 240 240 240 240 240 240 240 240 240 240 240 240 240 240 240 240 240 240
                240 240 240 240 240 240 240 240 240 240 240 240 240 240 240 240 240 240 240 240 240 240
                240 240 240 240 240 240 240 240 240 240 240 240 240 240 240 240 240 240 240 240 240 240
                240 240 240 240 240 240 240 240 240 240 240 240 240 240 240 240 240 240 240 240 240 240
                240 240 240 240 240 240 240 240 240 240 240 240 240 240 240 240 240 240 240 240 240 240
                240 240 240 240 240 240 240 240 240 240 240 240 240 240 240 240 240 240 240 240 240 240
                240 240 240 240 240 240 240 240 240 240 240 240 240 240 240 240 240 240 240 240 240 240
                240 240 240 240 240 240 240 240 240 240 240 240 240 240 240 240 240 240 240 240 240 240
                240 240 240 240 240 240 240 240 240 240 240 240 240 240 240 240 240 240 240 240 240 240
                240 240 240 240 240 240 240 240 240 240 240 240 240 240 240 240 240 240 240 240 240 240
                240 240 240 240 240 240 240 240 240 240 240 240 240 240 240 240 240 240 240 240 240 240
                240 240 240 240 240 240 240 240 240 240 240 240 240 240 240 240 240 240 240 240 240 240
                240 240 240 240 240 240 240 240 240 240 240 240 240 240 240 240 240 240 240 240 240 240
                240 240 240 240 240 240 240 240 240 240 240 240 240 240 240 240 240 240 240 240 240 240
                240 240 240 240 240 240 240 240 240 240 240 240 240 240 240 240 240 240 240 240 240 240
                240 240 240 240 240 240 240 240 240 240 240 240 240 240 240 240 240 240 240 240 240 240
                240 240 240 240 240 240 240 240 240 240 240 240 240 240 240 240 240 240 240 240 240 240
                240 240 240 240 240 240 240 240 240 240 240 240 240 240 240 240 240 240 240 240 240 240
                240 240 240 240 240 240 240 240 240 240 240 240 240 240 240 240 240 240 240 240 240 240
                240 240 240 240 240 240 240 240 240 240 240 240 240 240 240 240 240 240 240 240 240 240
                240 240 240 240 240 240 240 240 240 240 240 240 240 240 240 240 240 240 240 240 240 240
                240 240 240>;

            PS_Config_Lmt_FW_CC_P = <
                314 314 314 314 314 314 314 314 314 314 314 314 314 314 314 314 314 314 314 314 314 314
                314 314 314 314 314 314 314 314 314 314 314 314 314 314 314 314 314 314 314 314 314 314
                314 314 314 314 314 314 314 314 314 314 314 314 314 314 314 314 314 314 314 314 314 314
                314 314 314 314 314 314 314 314 314 314 314 314 314 314 314 314 314 314 314 314 314 314
                314 314 314 314 314 314 314 314 314 314 314 314 314 314 314 314 314 314 314 314 314 314
                314 314 314 314 314 314 314 314 314 314 314 314 314 314 314 314 314 314 314 314 314 314
                314 314 314 314 314 314 314 314 314 314 314 314 314 314 314 314 314 314 314 314 314 314
                314 314 314 314 314 314 314 314 314 314 314 314 314 314 314 314 314 314 314 314 314 314
                314 314 314 314 314 314 314 314 314 314 314 314 314 314 314 314 314 314 314 314 314 314
                314 314 314 314 314 314 314 314 314 314 314 314 314 314 314 314 314 314 314 314 314 314
                314 314 314 314 314 314 314 314 314 314 314 314 314 314 314 314 314 314 314 314 314 314
                314 314 314 314 314 314 314 314 314 314 314 314 314 314 314 314 314 314 314 314 314 314
                314 314 314 314 314 314 314 314 314 314 314 314 314 314 314 314 314 314 314 314 314 314
                314 314 314 314 314 314 314 314 314 314 314 314 314 314 314 314 314 314 314 314 314 314
                314 314 314 314 314 314 314 314 314 314 314 314 314 314 314 314 314 314 314 314 314 314
                314 314 314 314 314 314 314 314 314 314 314 314 314 314 314 314 314 314 314 314 314 314
                314 314 314 314 314 314 314 314 314 314 314 314 314 314 314 314 314 314 314 314 314 314
                314 314 314 314 314 314 314 314 314 314 314 314 314 314 314 314 314 314 314 314 314 314
                314 314 314 314 314 314 314 314 314 314 314 314 314 314 314 314 314 314 314 314 314 314
                314 314 314 314 314 314 314 314 314 314 314 314 314 314 314 314 314 314 314 314 314 314
                314 314 314 314 314 314 314 314 314 314 314 314 314 314 314 314 314 314 314 314 314 314
                314 314 314 314 314 314 314 314 314 314 314 314 314 314 314 314 314 314 314 314 314 314
                314 314 314 314 314 314 314 314 314 314 314 314 314 314 314 314 314 314 314 314 314 314
                314 314 314 314 314 314 314 314 314 314 314 314 314 314 314 314 314 314 314 314 314 314
                314 314 314 314 314 314 314 314 314 314 314 314 314 314 314 314 314 314 314 314 314 314
                314 314 314 314 314 314 314 314 314 314 314 314 314 314 314 314 314 314 314 314 314 314
                314 314 314 314 314 314 314 314 314 314 314 314 314 314 314 314 314 314 314 314 314 314
                314 314 314 314 314 314 314 314 314 314 314 314 314 314 314 314 314 314 314 314 314 314
                314 314 314 314 314 314 314 314 314 314 314 314 314 314 314 314 314 314 314 314 314 314
                314 314 314 314 314 314 314 314 314 314 314 314 314 314 314 314 314 314 314 314 314 314
                314 314 314 314 314 314 314 314 314 314 314 314 314 314 314 314 314 314 314 314 314 314
                314 314 314 314 314 314 314 314 314 314 314 314 314 314 314 314 314 314 314 314 314 314
                314 314 314 314 314 314 314 314 314 314 314 314 314 314 314 314 314 314 314 314 314 314
                314 314 314 314 314 314 314 314 314 314 314 314 314 314 314 314 314 314 314 314 314 314
                314 314 314 314 314 314 314 314 314 314 314 314 314 314 314 314 314 314 314 314 314 314
                314 314 314 314 314 314 314 314 314 314 314 314 314 314 314 314 314 314 314 314 314 314
                314 314 314>;

            PS_Config_Lmt_FW_CC_N = <
                0 0 0 0 0 0 0 0 0 0 0 0 0 0 0 0 0 0 0 0 0 0
                0 0 0 0 0 0 0 0 0 0 0 0 0 0 0 0 0 0 0 0 0 0
                0 0 0 0 0 0 0 0 0 0 0 0 0 0 0 0 0 0 0 0 0 0
                0 0 0 0 0 0 0 0 0 0 0 0 0 0 0 0 0 0 0 0 0 0
                0 0 0 0 0 0 0 0 0 0 0 0 0 0 0 0 0 0 0 0 0 0
                0 0 0 0 0 0 0 0 0 0 0 0 0 0 0 0 0 0 0 0 0 0
                0 0 0 0 0 0 0 0 0 0 0 0 0 0 0 0 0 0 0 0 0 0
                0 0 0 0 0 0 0 0 0 0 0 0 0 0 0 0 0 0 0 0 0 0
                0 0 0 0 0 0 0 0 0 0 0 0 0 0 0 0 0 0 0 0 0 0
                0 0 0 0 0 0 0 0 0 0 0 0 0 0 0 0 0 0 0 0 0 0
                0 0 0 0 0 0 0 0 0 0 0 0 0 0 0 0 0 0 0 0 0 0
                0 0 0 0 0 0 0 0 0 0 0 0 0 0 0 0 0 0 0 0 0 0
                0 0 0 0 0 0 0 0 0 0 0 0 0 0 0 0 0 0 0 0 0 0
                0 0 0 0 0 0 0 0 0 0 0 0 0 0 0 0 0 0 0 0 0 0
                0 0 0 0 0 0 0 0 0 0 0 0 0 0 0 0 0 0 0 0 0 0
                0 0 0 0 0 0 0 0 0 0 0 0 0 0 0 0 0 0 0 0 0 0
                0 0 0 0 0 0 0 0 0 0 0 0 0 0 0 0 0 0 0 0 0 0
                0 0 0 0 0 0 0 0 0 0 0 0 0 0 0 0 0 0 0 0 0 0
                0 0 0 0 0 0 0 0 0 0 0 0 0 0 0 0 0 0 0 0 0 0
                0 0 0 0 0 0 0 0 0 0 0 0 0 0 0 0 0 0 0 0 0 0
                0 0 0 0 0 0 0 0 0 0 0 0 0 0 0 0 0 0 0 0 0 0
                0 0 0 0 0 0 0 0 0 0 0 0 0 0 0 0 0 0 0 0 0 0
                0 0 0 0 0 0 0 0 0 0 0 0 0 0 0 0 0 0 0 0 0 0
                0 0 0 0 0 0 0 0 0 0 0 0 0 0 0 0 0 0 0 0 0 0
                0 0 0 0 0 0 0 0 0 0 0 0 0 0 0 0 0 0 0 0 0 0
                0 0 0 0 0 0 0 0 0 0 0 0 0 0 0 0 0 0 0 0 0 0
                0 0 0 0 0 0 0 0 0 0 0 0 0 0 0 0 0 0 0 0 0 0
                0 0 0 0 0 0 0 0 0 0 0 0 0 0 0 0 0 0 0 0 0 0
                0 0 0 0 0 0 0 0 0 0 0 0 0 0 0 0 0 0 0 0 0 0
                0 0 0 0 0 0 0 0 0 0 0 0 0 0 0 0 0 0 0 0 0 0
                0 0 0 0 0 0 0 0 0 0 0 0 0 0 0 0 0 0 0 0 0 0
                0 0 0 0 0 0 0 0 0 0 0 0 0 0 0 0 0 0 0 0 0 0
                0 0 0 0 0 0 0 0 0 0 0 0 0 0 0 0 0 0 0 0 0 0
                0 0 0 0 0 0 0 0 0 0 0 0 0 0 0 0 0 0 0 0 0 0
                0 0 0 0 0 0 0 0 0 0 0 0 0 0 0 0 0 0 0 0 0 0
                0 0 0 0 0 0 0 0 0 0 0 0 0 0 0 0 0 0 0 0 0 0
                0 0 0>;

            PS_Config_Lmt_FW_Diff_P = <
                200 200 200 200 200 200 200 200 200 200 200 200 200 200 200 200 200 200 200 200 200 200
                200 200 200 200 200 200 200 200 200 200 200 200 200 200 200 200 200 200 200 200 200 200
                200 200 200 200 200 200 200 200 200 200 200 200 200 200 200 200 200 200 200 200 200 200
                200 200 200 200 200 200 200 200 200 200 200 200 200 200 200 200 200 200 200 200 200 200
                200 200 200 200 200 200 200 200 200 200 200 200 200 200 200 200 200 200 200 200 200 200
                200 200 200 200 200 200 200 200 200 200 200 200 200 200 200 200 200 200 200 200 200 200
                200 200 200 200 200 200 200 200 200 200 200 200 200 200 200 200 200 200 200 200 200 200
                200 200 200 200 200 200 200 200 200 200 200 200 200 200 200 200 200 200 200 200 200 200
                200 200 200 200 200 200 200 200 200 200 200 200 200 200 200 200 200 200 200 200 200 200
                200 200 200 200 200 200 200 200 200 200 200 200 200 200 200 200 200 200 200 200 200 200
                200 200 200 200 200 200 200 200 200 200 200 200 200 200 200 200 200 200 200 200 200 200
                200 200 200 200 200 200 200 200 200 200 200 200 200 200 200 200 200 200 200 200 200 200
                200 200 200 200 200 200 200 200 200 200 200 200 200 200 200 200 200 200 200 200 200 200
                200 200 200 200 200 200 200 200 200 200 200 200 200 200 200 200 200 200 200 200 200 200
                200 200 200 200 200 200 200 200 200 200 200 200 200 200 200 200 200 200 200 200 200 200
                200 200 200 200 200 200 200 200 200 200 200 200 200 200 200 200 200 200 200 200 200 200
                200 200 200 200 200 200 200 200 200 200 200 200 200 200 200 200 200 200 200 200 200 200
                200 200 200 200 200 200 200 200 200 200 200 200 200 200 200 200 200 200 200 200 200 200
                200 200 200 200 200 200 200 200 200 200 200 200 200 200 200 200 200 200 200 200 200 200
                200 200 200 200 200 200 200 200 200 200 200 200 200 200 200 200 200 200 200 200 200 200
                200 200 200 200 200 200 200 200 200 200 200 200 200 200 200 200 200 200 200 200 200 200
                200 200 200 200 200 200 200 200 200 200 200 200 200 200 200 200 200 200 200 200 200 200
                200 200 200 200 200 200 200 200 200 200 200 200 200 200 200 200 200 200 200 200 200 200
                200 200 200 200 200 200 200 200 200 200 200 200 200 200 200 200 200 200 200 200 200 200
                200 200 200 200 200 200 200 200 200 200 200 200 200 200 200 200 200 200 200 200 200 200
                200 200 200 200 200 200 200 200 200 200 200 200 200 200 200 200 200 200 200 200 200 200
                200 200 200 200 200 200 200 200 200 200 200 200 200 200 200 200 200 200 200 200 200 200
                200 200 200 200 200 200 200 200 200 200 200 200 200 200 200 200 200 200 200 200 200 200
                200 200 200 200 200 200 200 200 200 200 200 200 200 200 200 200 200 200 200 200 200 200
                200 200 200 200 200 200 200 200 200 200 200 200 200 200 200 200 200 200 200 200 200 200
                200 200 200 200 200 200 200 200 200 200 200 200 200 200 200 200 200 200 200 200 200 200
                200 200 200 200 200 200 200 200 200 200 200 200 200 200 200 200 200 200 200 200 200 200
                200 200 200 200 200 200 200 200 200 200 200 200 200 200 200 200 200 200 200 200 200 200
                200 200 200 200 200 200 200 200 200 200 200 200 200 200 200 200 200 200 200 200 200 200
                200 200 200 200 200 200 200 200 200 200 200 200 200 200 200 200 200 200 200 200 200 200
                200 200 200 200 200 200 200 200 200 200 200 200 200 200 200 200 200 200 200 200 200 200
                200 200 200>;

            PS_Config_Lmt_FW_Diff_N = <
                (-200) (-200) (-200) (-200) (-200) (-200) (-200) (-200) (-200) (-200) (-200) (-200) (-200) (-200) (-200) (-200) (-200) (-200) (-200) (-200) (-200) (-200)
                (-200) (-200) (-200) (-200) (-200) (-200) (-200) (-200) (-200) (-200) (-200) (-200) (-200) (-200) (-200) (-200) (-200) (-200) (-200) (-200) (-200) (-200)
                (-200) (-200) (-200) (-200) (-200) (-200) (-200) (-200) (-200) (-200) (-200) (-200) (-200) (-200) (-200) (-200) (-200) (-200) (-200) (-200) (-200) (-200)
                (-200) (-200) (-200) (-200) (-200) (-200) (-200) (-200) (-200) (-200) (-200) (-200) (-200) (-200) (-200) (-200) (-200) (-200) (-200) (-200) (-200) (-200)
                (-200) (-200) (-200) (-200) (-200) (-200) (-200) (-200) (-200) (-200) (-200) (-200) (-200) (-200) (-200) (-200) (-200) (-200) (-200) (-200) (-200) (-200)
                (-200) (-200) (-200) (-200) (-200) (-200) (-200) (-200) (-200) (-200) (-200) (-200) (-200) (-200) (-200) (-200) (-200) (-200) (-200) (-200) (-200) (-200)
                (-200) (-200) (-200) (-200) (-200) (-200) (-200) (-200) (-200) (-200) (-200) (-200) (-200) (-200) (-200) (-200) (-200) (-200) (-200) (-200) (-200) (-200)
                (-200) (-200) (-200) (-200) (-200) (-200) (-200) (-200) (-200) (-200) (-200) (-200) (-200) (-200) (-200) (-200) (-200) (-200) (-200) (-200) (-200) (-200)
                (-200) (-200) (-200) (-200) (-200) (-200) (-200) (-200) (-200) (-200) (-200) (-200) (-200) (-200) (-200) (-200) (-200) (-200) (-200) (-200) (-200) (-200)
                (-200) (-200) (-200) (-200) (-200) (-200) (-200) (-200) (-200) (-200) (-200) (-200) (-200) (-200) (-200) (-200) (-200) (-200) (-200) (-200) (-200) (-200)
                (-200) (-200) (-200) (-200) (-200) (-200) (-200) (-200) (-200) (-200) (-200) (-200) (-200) (-200) (-200) (-200) (-200) (-200) (-200) (-200) (-200) (-200)
                (-200) (-200) (-200) (-200) (-200) (-200) (-200) (-200) (-200) (-200) (-200) (-200) (-200) (-200) (-200) (-200) (-200) (-200) (-200) (-200) (-200) (-200)
                (-200) (-200) (-200) (-200) (-200) (-200) (-200) (-200) (-200) (-200) (-200) (-200) (-200) (-200) (-200) (-200) (-200) (-200) (-200) (-200) (-200) (-200)
                (-200) (-200) (-200) (-200) (-200) (-200) (-200) (-200) (-200) (-200) (-200) (-200) (-200) (-200) (-200) (-200) (-200) (-200) (-200) (-200) (-200) (-200)
                (-200) (-200) (-200) (-200) (-200) (-200) (-200) (-200) (-200) (-200) (-200) (-200) (-200) (-200) (-200) (-200) (-200) (-200) (-200) (-200) (-200) (-200)
                (-200) (-200) (-200) (-200) (-200) (-200) (-200) (-200) (-200) (-200) (-200) (-200) (-200) (-200) (-200) (-200) (-200) (-200) (-200) (-200) (-200) (-200)
                (-200) (-200) (-200) (-200) (-200) (-200) (-200) (-200) (-200) (-200) (-200) (-200) (-200) (-200) (-200) (-200) (-200) (-200) (-200) (-200) (-200) (-200)
                (-200) (-200) (-200) (-200) (-200) (-200) (-200) (-200) (-200) (-200) (-200) (-200) (-200) (-200) (-200) (-200) (-200) (-200) (-200) (-200) (-200) (-200)
                (-200) (-200) (-200) (-200) (-200) (-200) (-200) (-200) (-200) (-200) (-200) (-200) (-200) (-200) (-200) (-200) (-200) (-200) (-200) (-200) (-200) (-200)
                (-200) (-200) (-200) (-200) (-200) (-200) (-200) (-200) (-200) (-200) (-200) (-200) (-200) (-200) (-200) (-200) (-200) (-200) (-200) (-200) (-200) (-200)
                (-200) (-200) (-200) (-200) (-200) (-200) (-200) (-200) (-200) (-200) (-200) (-200) (-200) (-200) (-200) (-200) (-200) (-200) (-200) (-200) (-200) (-200)
                (-200) (-200) (-200) (-200) (-200) (-200) (-200) (-200) (-200) (-200) (-200) (-200) (-200) (-200) (-200) (-200) (-200) (-200) (-200) (-200) (-200) (-200)
                (-200) (-200) (-200) (-200) (-200) (-200) (-200) (-200) (-200) (-200) (-200) (-200) (-200) (-200) (-200) (-200) (-200) (-200) (-200) (-200) (-200) (-200)
                (-200) (-200) (-200) (-200) (-200) (-200) (-200) (-200) (-200) (-200) (-200) (-200) (-200) (-200) (-200) (-200) (-200) (-200) (-200) (-200) (-200) (-200)
                (-200) (-200) (-200) (-200) (-200) (-200) (-200) (-200) (-200) (-200) (-200) (-200) (-200) (-200) (-200) (-200) (-200) (-200) (-200) (-200) (-200) (-200)
                (-200) (-200) (-200) (-200) (-200) (-200) (-200) (-200) (-200) (-200) (-200) (-200) (-200) (-200) (-200) (-200) (-200) (-200) (-200) (-200) (-200) (-200)
                (-200) (-200) (-200) (-200) (-200) (-200) (-200) (-200) (-200) (-200) (-200) (-200) (-200) (-200) (-200) (-200) (-200) (-200) (-200) (-200) (-200) (-200)
                (-200) (-200) (-200) (-200) (-200) (-200) (-200) (-200) (-200) (-200) (-200) (-200) (-200) (-200) (-200) (-200) (-200) (-200) (-200) (-200) (-200) (-200)
                (-200) (-200) (-200) (-200) (-200) (-200) (-200) (-200) (-200) (-200) (-200) (-200) (-200) (-200) (-200) (-200) (-200) (-200) (-200) (-200) (-200) (-200)
                (-200) (-200) (-200) (-200) (-200) (-200) (-200) (-200) (-200) (-200) (-200) (-200) (-200) (-200) (-200) (-200) (-200) (-200) (-200) (-200) (-200) (-200)
                (-200) (-200) (-200) (-200) (-200) (-200) (-200) (-200) (-200) (-200) (-200) (-200) (-200) (-200) (-200) (-200) (-200) (-200) (-200) (-200) (-200) (-200)
                (-200) (-200) (-200) (-200) (-200) (-200) (-200) (-200) (-200) (-200) (-200) (-200) (-200) (-200) (-200) (-200) (-200) (-200) (-200) (-200) (-200) (-200)
                (-200) (-200) (-200) (-200) (-200) (-200) (-200) (-200) (-200) (-200) (-200) (-200) (-200) (-200) (-200) (-200) (-200) (-200) (-200) (-200) (-200) (-200)
                (-200) (-200) (-200) (-200) (-200) (-200) (-200) (-200) (-200) (-200) (-200) (-200) (-200) (-200) (-200) (-200) (-200) (-200) (-200) (-200) (-200) (-200)
                (-200) (-200) (-200) (-200) (-200) (-200) (-200) (-200) (-200) (-200) (-200) (-200) (-200) (-200) (-200) (-200) (-200) (-200) (-200) (-200) (-200) (-200)
                (-200) (-200) (-200) (-200) (-200) (-200) (-200) (-200) (-200) (-200) (-200) (-200) (-200) (-200) (-200) (-200) (-200) (-200) (-200) (-200) (-200) (-200)
                (-200) (-200) (-200)>;

            PS_Config_Diff_Test_Frame = <50>;

            PS_Config_Lmt_LPWG_Rawdata_P = <
                3840 3840 3840 3840 3840 3840 3840 3840 3840 3840 3840 3840 3840 3840 3840 3840 3840 3840 3840 3840 3840 3840
                3840 3840 3840 3840 3840 3840 3840 3840 3840 3840 3840 3840 3840 3840 3840 3840 3840 3840 3840 3840 3840 3840
                3840 3840 3840 3840 3840 3840 3840 3840 3840 3840 3840 3840 3840 3840 3840 3840 3840 3840 3840 3840 3840 3840
                3840 3840 3840 3840 3840 3840 3840 3840 3840 3840 3840 3840 3840 3840 3840 3840 3840 3840 3840 3840 3840 3840
                3840 3840 3840 3840 3840 3840 3840 3840 3840 3840 3840 3840 3840 3840 3840 3840 3840 3840 3840 3840 3840 3840
                3840 3840 3840 3840 3840 3840 3840 3840 3840 3840 3840 3840 3840 3840 3840 3840 3840 3840 3840 3840 3840 3840
                3840 3840 3840 3840 3840 3840 3840 3840 3840 3840 3840 3840 3840 3840 3840 3840 3840 3840 3840 3840 3840 3840
                3840 3840 3840 3840 3840 3840 3840 3840 3840 3840 3840 3840 3840 3840 3840 3840 3840 3840 3840 3840 3840 3840
                3840 3840 3840 3840 3840 3840 3840 3840 3840 3840 3840 3840 3840 3840 3840 3840 3840 3840 3840 3840 3840 3840
                3840 3840 3840 3840 3840 3840 3840 3840 3840 3840 3840 3840 3840 3840 3840 3840 3840 3840 3840 3840 3840 3840
                3840 3840 3840 3840 3840 3840 3840 3840 3840 3840 3840 3840 3840 3840 3840 3840 3840 3840 3840 3840 3840 3840
                3840 3840 3840 3840 3840 3840 3840 3840 3840 3840 3840 3840 3840 3840 3840 3840 3840 3840 3840 3840 3840 3840
                3840 3840 3840 3840 3840 3840 3840 3840 3840 3840 3840 3840 3840 3840 3840 3840 3840 3840 3840 3840 3840 3840
                3840 3840 3840 3840 3840 3840 3840 3840 3840 3840 3840 3840 3840 3840 3840 3840 3840 3840 3840 3840 3840 3840
                3840 3840 3840 3840 3840 3840 3840 3840 3840 3840 3840 3840 3840 3840 3840 3840 3840 3840 3840 3840 3840 3840
                3840 3840 3840 3840 3840 3840 3840 3840 3840 3840 3840 3840 3840 3840 3840 3840 3840 3840 3840 3840 3840 3840
                3840 3840 3840 3840 3840 3840 3840 3840 3840 3840 3840 3840 3840 3840 3840 3840 3840 3840 3840 3840 3840 3840
                3840 3840 3840 3840 3840 3840 3840 3840 3840 3840 3840 3840 3840 3840 3840 3840 3840 3840 3840 3840 3840 3840
                3840 3840 3840 3840 3840 3840 3840 3840 3840 3840 3840 3840 3840 3840 3840 3840 3840 3840 3840 3840 3840 3840
                3840 3840 3840 3840 3840 3840 3840 3840 3840 3840 3840 3840 3840 3840 3840 3840 3840 3840 3840 3840 3840 3840
                3840 3840 3840 3840 3840 3840 3840 3840 3840 3840 3840 3840 3840 3840 3840 3840 3840 3840 3840 3840 3840 3840
                3840 3840 3840 3840 3840 3840 3840 3840 3840 3840 3840 3840 3840 3840 3840 3840 3840 3840 3840 3840 3840 3840
                3840 3840 3840 3840 3840 3840 3840 3840 3840 3840 3840 3840 3840 3840 3840 3840 3840 3840 3840 3840 3840 3840
                3840 3840 3840 3840 3840 3840 3840 3840 3840 3840 3840 3840 3840 3840 3840 3840 3840 3840 3840 3840 3840 3840
                3840 3840 3840 3840 3840 3840 3840 3840 3840 3840 3840 3840 3840 3840 3840 3840 3840 3840 3840 3840 3840 3840
                3840 3840 3840 3840 3840 3840 3840 3840 3840 3840 3840 3840 3840 3840 3840 3840 3840 3840 3840 3840 3840 3840
                3840 3840 3840 3840 3840 3840 3840 3840 3840 3840 3840 3840 3840 3840 3840 3840 3840 3840 3840 3840 3840 3840
                3840 3840 3840 3840 3840 3840 3840 3840 3840 3840 3840 3840 3840 3840 3840 3840 3840 3840 3840 3840 3840 3840
                3840 3840 3840 3840 3840 3840 3840 3840 3840 3840 3840 3840 3840 3840 3840 3840 3840 3840 3840 3840 3840 3840
                3840 3840 3840 3840 3840 3840 3840 3840 3840 3840 3840 3840 3840 3840 3840 3840 3840 3840 3840 3840 3840 3840
                3840 3840 3840 3840 3840 3840 3840 3840 3840 3840 3840 3840 3840 3840 3840 3840 3840 3840 3840 3840 3840 3840
                3840 3840 3840 3840 3840 3840 3840 3840 3840 3840 3840 3840 3840 3840 3840 3840 3840 3840 3840 3840 3840 3840
                3840 3840 3840 3840 3840 3840 3840 3840 3840 3840 3840 3840 3840 3840 3840 3840 3840 3840 3840 3840 3840 3840
                3840 3840 3840 3840 3840 3840 3840 3840 3840 3840 3840 3840 3840 3840 3840 3840 3840 3840 3840 3840 3840 3840
                3840 3840 3840 3840 3840 3840 3840 3840 3840 3840 3840 3840 3840 3840 3840 3840 3840 3840 3840 3840 3840 3840
                3840 3840 3840 3840 3840 3840 3840 3840 3840 3840 3840 3840 3840 3840 3840 3840 3840 3840 3840 3840 3840 3840
                3840 3840 3840>;

            PS_Config_Lmt_LPWG_Rawdata_N = <
                240 240 240 240 240 240 240 240 240 240 240 240 240 240 240 240 240 240 240 240 240 240
                240 240 240 240 240 240 240 240 240 240 240 240 240 240 240 240 240 240 240 240 240 240
                240 240 240 240 240 240 240 240 240 240 240 240 240 240 240 240 240 240 240 240 240 240
                240 240 240 240 240 240 240 240 240 240 240 240 240 240 240 240 240 240 240 240 240 240
                240 240 240 240 240 240 240 240 240 240 240 240 240 240 240 240 240 240 240 240 240 240
                240 240 240 240 240 240 240 240 240 240 240 240 240 240 240 240 240 240 240 240 240 240
                240 240 240 240 240 240 240 240 240 240 240 240 240 240 240 240 240 240 240 240 240 240
                240 240 240 240 240 240 240 240 240 240 240 240 240 240 240 240 240 240 240 240 240 240
                240 240 240 240 240 240 240 240 240 240 240 240 240 240 240 240 240 240 240 240 240 240
                240 240 240 240 240 240 240 240 240 240 240 240 240 240 240 240 240 240 240 240 240 240
                240 240 240 240 240 240 240 240 240 240 240 240 240 240 240 240 240 240 240 240 240 240
                240 240 240 240 240 240 240 240 240 240 240 240 240 240 240 240 240 240 240 240 240 240
                240 240 240 240 240 240 240 240 240 240 240 240 240 240 240 240 240 240 240 240 240 240
                240 240 240 240 240 240 240 240 240 240 240 240 240 240 240 240 240 240 240 240 240 240
                240 240 240 240 240 240 240 240 240 240 240 240 240 240 240 240 240 240 240 240 240 240
                240 240 240 240 240 240 240 240 240 240 240 240 240 240 240 240 240 240 240 240 240 240
                240 240 240 240 240 240 240 240 240 240 240 240 240 240 240 240 240 240 240 240 240 240
                240 240 240 240 240 240 240 240 240 240 240 240 240 240 240 240 240 240 240 240 240 240
                240 240 240 240 240 240 240 240 240 240 240 240 240 240 240 240 240 240 240 240 240 240
                240 240 240 240 240 240 240 240 240 240 240 240 240 240 240 240 240 240 240 240 240 240
                240 240 240 240 240 240 240 240 240 240 240 240 240 240 240 240 240 240 240 240 240 240
                240 240 240 240 240 240 240 240 240 240 240 240 240 240 240 240 240 240 240 240 240 240
                240 240 240 240 240 240 240 240 240 240 240 240 240 240 240 240 240 240 240 240 240 240
                240 240 240 240 240 240 240 240 240 240 240 240 240 240 240 240 240 240 240 240 240 240
                240 240 240 240 240 240 240 240 240 240 240 240 240 240 240 240 240 240 240 240 240 240
                240 240 240 240 240 240 240 240 240 240 240 240 240 240 240 240 240 240 240 240 240 240
                240 240 240 240 240 240 240 240 240 240 240 240 240 240 240 240 240 240 240 240 240 240
                240 240 240 240 240 240 240 240 240 240 240 240 240 240 240 240 240 240 240 240 240 240
                240 240 240 240 240 240 240 240 240 240 240 240 240 240 240 240 240 240 240 240 240 240
                240 240 240 240 240 240 240 240 240 240 240 240 240 240 240 240 240 240 240 240 240 240
                240 240 240 240 240 240 240 240 240 240 240 240 240 240 240 240 240 240 240 240 240 240
                240 240 240 240 240 240 240 240 240 240 240 240 240 240 240 240 240 240 240 240 240 240
                240 240 240 240 240 240 240 240 240 240 240 240 240 240 240 240 240 240 240 240 240 240
                240 240 240 240 240 240 240 240 240 240 240 240 240 240 240 240 240 240 240 240 240 240
                240 240 240 240 240 240 240 240 240 240 240 240 240 240 240 240 240 240 240 240 240 240
                240 240 240 240 240 240 240 240 240 240 240 240 240 240 240 240 240 240 240 240 240 240
                240 240 240>;

            PS_Config_Lmt_LPWG_Diff_P = <
                75 75 75 75 75 75 75 75 75 75 75 75 75 75 75 75 75 75 75 75 75 75
                75 75 75 75 75 75 75 75 75 75 75 75 75 75 75 75 75 75 75 75 75 75
                75 75 75 75 75 75 75 75 75 75 75 75 75 75 75 75 75 75 75 75 75 75
                75 75 75 75 75 75 75 75 75 75 75 75 75 75 75 75 75 75 75 75 75 75
                75 75 75 75 75 75 75 75 75 75 75 75 75 75 75 75 75 75 75 75 75 75
                75 75 75 75 75 75 75 75 75 75 75 75 75 75 75 75 75 75 75 75 75 75
                75 75 75 75 75 75 75 75 75 75 75 75 75 75 75 75 75 75 75 75 75 75
                75 75 75 75 75 75 75 75 75 75 75 75 75 75 75 75 75 75 75 75 75 75
                75 75 75 75 75 75 75 75 75 75 75 75 75 75 75 75 75 75 75 75 75 75
                75 75 75 75 75 75 75 75 75 75 75 75 75 75 75 75 75 75 75 75 75 75
                75 75 75 75 75 75 75 75 75 75 75 75 75 75 75 75 75 75 75 75 75 75
                75 75 75 75 75 75 75 75 75 75 75 75 75 75 75 75 75 75 75 75 75 75
                75 75 75 75 75 75 75 75 75 75 75 75 75 75 75 75 75 75 75 75 75 75
                75 75 75 75 75 75 75 75 75 75 75 75 75 75 75 75 75 75 75 75 75 75
                75 75 75 75 75 75 75 75 75 75 75 75 75 75 75 75 75 75 75 75 75 75
                75 75 75 75 75 75 75 75 75 75 75 75 75 75 75 75 75 75 75 75 75 75
                75 75 75 75 75 75 75 75 75 75 75 75 75 75 75 75 75 75 75 75 75 75
                75 75 75 75 75 75 75 75 75 75 75 75 75 75 75 75 75 75 75 75 75 75
                75 75 75 75 75 75 75 75 75 75 75 75 75 75 75 75 75 75 75 75 75 75
                75 75 75 75 75 75 75 75 75 75 75 75 75 75 75 75 75 75 75 75 75 75
                75 75 75 75 75 75 75 75 75 75 75 75 75 75 75 75 75 75 75 75 75 75
                75 75 75 75 75 75 75 75 75 75 75 75 75 75 75 75 75 75 75 75 75 75
                75 75 75 75 75 75 75 75 75 75 75 75 75 75 75 75 75 75 75 75 75 75
                75 75 75 75 75 75 75 75 75 75 75 75 75 75 75 75 75 75 75 75 75 75
                75 75 75 75 75 75 75 75 75 75 75 75 75 75 75 75 75 75 75 75 75 75
                75 75 75 75 75 75 75 75 75 75 75 75 75 75 75 75 75 75 75 75 75 75
                75 75 75 75 75 75 75 75 75 75 75 75 75 75 75 75 75 75 75 75 75 75
                75 75 75 75 75 75 75 75 75 75 75 75 75 75 75 75 75 75 75 75 75 75
                75 75 75 75 75 75 75 75 75 75 75 75 75 75 75 75 75 75 75 75 75 75
                75 75 75 75 75 75 75 75 75 75 75 75 75 75 75 75 75 75 75 75 75 75
                75 75 75 75 75 75 75 75 75 75 75 75 75 75 75 75 75 75 75 75 75 75
                75 75 75 75 75 75 75 75 75 75 75 75 75 75 75 75 75 75 75 75 75 75
                75 75 75 75 75 75 75 75 75 75 75 75 75 75 75 75 75 75 75 75 75 75
                75 75 75 75 75 75 75 75 75 75 75 75 75 75 75 75 75 75 75 75 75 75
                75 75 75 75 75 75 75 75 75 75 75 75 75 75 75 75 75 75 75 75 75 75
                75 75 75 75 75 75 75 75 75 75 75 75 75 75 75 75 75 75 75 75 75 75
                75 75 75>;

            PS_Config_Lmt_LPWG_Diff_N = <
                (-75) (-75) (-75) (-75) (-75) (-75) (-75) (-75) (-75) (-75) (-75) (-75) (-75) (-75) (-75) (-75) (-75) (-75) (-75) (-75) (-75) (-75) (-75) (-75) (-75) (-75)
                (-75) (-75) (-75) (-75) (-75) (-75) (-75) (-75) (-75) (-75) (-75) (-75) (-75) (-75) (-75) (-75) (-75) (-75) (-75) (-75) (-75) (-75) (-75) (-75) (-75) (-75)
                (-75) (-75) (-75) (-75) (-75) (-75) (-75) (-75) (-75) (-75) (-75) (-75) (-75) (-75) (-75) (-75) (-75) (-75) (-75) (-75) (-75) (-75) (-75) (-75) (-75) (-75)
                (-75) (-75) (-75) (-75) (-75) (-75) (-75) (-75) (-75) (-75) (-75) (-75) (-75) (-75) (-75) (-75) (-75) (-75) (-75) (-75) (-75) (-75) (-75) (-75) (-75) (-75)
                (-75) (-75) (-75) (-75) (-75) (-75) (-75) (-75) (-75) (-75) (-75) (-75) (-75) (-75) (-75) (-75) (-75) (-75) (-75) (-75) (-75) (-75) (-75) (-75) (-75) (-75)
                (-75) (-75) (-75) (-75) (-75) (-75) (-75) (-75) (-75) (-75) (-75) (-75) (-75) (-75) (-75) (-75) (-75) (-75) (-75) (-75) (-75) (-75) (-75) (-75) (-75) (-75)
                (-75) (-75) (-75) (-75) (-75) (-75) (-75) (-75) (-75) (-75) (-75) (-75) (-75) (-75) (-75) (-75) (-75) (-75) (-75) (-75) (-75) (-75) (-75) (-75) (-75) (-75)
                (-75) (-75) (-75) (-75) (-75) (-75) (-75) (-75) (-75) (-75) (-75) (-75) (-75) (-75) (-75) (-75) (-75) (-75) (-75) (-75) (-75) (-75) (-75) (-75) (-75) (-75)
                (-75) (-75) (-75) (-75) (-75) (-75) (-75) (-75) (-75) (-75) (-75) (-75) (-75) (-75) (-75) (-75) (-75) (-75) (-75) (-75) (-75) (-75) (-75) (-75) (-75) (-75)
                (-75) (-75) (-75) (-75) (-75) (-75) (-75) (-75) (-75) (-75) (-75) (-75) (-75) (-75) (-75) (-75) (-75) (-75) (-75) (-75) (-75) (-75) (-75) (-75) (-75) (-75)
                (-75) (-75) (-75) (-75) (-75) (-75) (-75) (-75) (-75) (-75) (-75) (-75) (-75) (-75) (-75) (-75) (-75) (-75) (-75) (-75) (-75) (-75) (-75) (-75) (-75) (-75)
                (-75) (-75) (-75) (-75) (-75) (-75) (-75) (-75) (-75) (-75) (-75) (-75) (-75) (-75) (-75) (-75) (-75) (-75) (-75) (-75) (-75) (-75) (-75) (-75) (-75) (-75)
                (-75) (-75) (-75) (-75) (-75) (-75) (-75) (-75) (-75) (-75) (-75) (-75) (-75) (-75) (-75) (-75) (-75) (-75) (-75) (-75) (-75) (-75) (-75) (-75) (-75) (-75)
                (-75) (-75) (-75) (-75) (-75) (-75) (-75) (-75) (-75) (-75) (-75) (-75) (-75) (-75) (-75) (-75) (-75) (-75) (-75) (-75) (-75) (-75) (-75) (-75) (-75) (-75)
                (-75) (-75) (-75) (-75) (-75) (-75) (-75) (-75) (-75) (-75) (-75) (-75) (-75) (-75) (-75) (-75) (-75) (-75) (-75) (-75) (-75) (-75) (-75) (-75) (-75) (-75)
                (-75) (-75) (-75) (-75) (-75) (-75) (-75) (-75) (-75) (-75) (-75) (-75) (-75) (-75) (-75) (-75) (-75) (-75) (-75) (-75) (-75) (-75) (-75) (-75) (-75) (-75)
                (-75) (-75) (-75) (-75) (-75) (-75) (-75) (-75) (-75) (-75) (-75) (-75) (-75) (-75) (-75) (-75) (-75) (-75) (-75) (-75) (-75) (-75) (-75) (-75) (-75) (-75)
                (-75) (-75) (-75) (-75) (-75) (-75) (-75) (-75) (-75) (-75) (-75) (-75) (-75) (-75) (-75) (-75) (-75) (-75) (-75) (-75) (-75) (-75) (-75) (-75) (-75) (-75)
                (-75) (-75) (-75) (-75) (-75) (-75) (-75) (-75) (-75) (-75) (-75) (-75) (-75) (-75) (-75) (-75) (-75) (-75) (-75) (-75) (-75) (-75) (-75) (-75) (-75) (-75)
                (-75) (-75) (-75) (-75) (-75) (-75) (-75) (-75) (-75) (-75) (-75) (-75) (-75) (-75) (-75) (-75) (-75) (-75) (-75) (-75) (-75) (-75) (-75) (-75) (-75) (-75)
                (-75) (-75) (-75) (-75) (-75) (-75) (-75) (-75) (-75) (-75) (-75) (-75) (-75) (-75) (-75) (-75) (-75) (-75) (-75) (-75) (-75) (-75) (-75) (-75) (-75) (-75)
                (-75) (-75) (-75) (-75) (-75) (-75) (-75) (-75) (-75) (-75) (-75) (-75) (-75) (-75) (-75) (-75) (-75) (-75) (-75) (-75) (-75) (-75) (-75) (-75) (-75) (-75)
                (-75) (-75) (-75) (-75) (-75) (-75) (-75) (-75) (-75) (-75) (-75) (-75) (-75) (-75) (-75) (-75) (-75) (-75) (-75) (-75) (-75) (-75) (-75) (-75) (-75) (-75)
                (-75) (-75) (-75) (-75) (-75) (-75) (-75) (-75) (-75) (-75) (-75) (-75) (-75) (-75) (-75) (-75) (-75) (-75) (-75) (-75) (-75) (-75) (-75) (-75) (-75) (-75)
                (-75) (-75) (-75) (-75) (-75) (-75) (-75) (-75) (-75) (-75) (-75) (-75) (-75) (-75) (-75) (-75) (-75) (-75) (-75) (-75) (-75) (-75) (-75) (-75) (-75) (-75)
                (-75) (-75) (-75) (-75) (-75) (-75) (-75) (-75) (-75) (-75) (-75) (-75) (-75) (-75) (-75) (-75) (-75) (-75) (-75) (-75) (-75) (-75) (-75) (-75) (-75) (-75)
                (-75) (-75) (-75) (-75) (-75) (-75) (-75) (-75) (-75) (-75) (-75) (-75) (-75) (-75) (-75) (-75) (-75) (-75) (-75) (-75) (-75) (-75) (-75) (-75) (-75) (-75)
                (-75) (-75) (-75) (-75) (-75) (-75) (-75) (-75) (-75) (-75) (-75) (-75) (-75) (-75) (-75) (-75) (-75) (-75) (-75) (-75) (-75) (-75) (-75) (-75) (-75) (-75)
                (-75) (-75) (-75) (-75) (-75) (-75) (-75) (-75) (-75) (-75) (-75) (-75) (-75) (-75) (-75) (-75) (-75) (-75) (-75) (-75) (-75) (-75) (-75) (-75) (-75) (-75)
                (-75) (-75) (-75) (-75) (-75) (-75) (-75) (-75) (-75) (-75) (-75) (-75) (-75) (-75) (-75) (-75) (-75) (-75) (-75) (-75) (-75) (-75) (-75) (-75) (-75) (-75)
                (-75) (-75) (-75) (-75) (-75) (-75) (-75) (-75) (-75) (-75) (-75) (-75) (-75) (-75) (-75) (-75) (-75) (-75) (-75) (-75) (-75) (-75) (-75) (-75) (-75) (-75)
                (-75) (-75) (-75) (-75) (-75) (-75) (-75) (-75) (-75) (-75) (-75) (-75) (-75) (-75) (-75) (-75) (-75) (-75) (-75) (-75) (-75) (-75) (-75) (-75) (-75) (-75)
                (-75) (-75) (-75) (-75) (-75) (-75) (-75) (-75) (-75) (-75) (-75) (-75) (-75) (-75) (-75) (-75) (-75) (-75) (-75) (-75) (-75) (-75) (-75) (-75) (-75) (-75)
                (-75) (-75) (-75) (-75) (-75) (-75) (-75) (-75) (-75) (-75) (-75) (-75) (-75) (-75) (-75) (-75) (-75) (-75) (-75) (-75) (-75) (-75) (-75) (-75) (-75) (-75)
                (-75) (-75) (-75) (-75) (-75) (-75) (-75) (-75) (-75) (-75) (-75) (-75) (-75) (-75) (-75) (-75) (-75) (-75) (-75) (-75) (-75) (-75) (-75) (-75) (-75) (-75)
                (-75) (-75) (-75) (-75) (-75) (-75) (-75) (-75) (-75) (-75) (-75) (-75) (-75) (-75) (-75) (-75) (-75) (-75) (-75) (-75) (-75) (-75) (-75) (-75) (-75) (-75)
                (-75) (-75) (-75)>;

            /* FDM config */
            FDM_X_Channel = <2>;

            PS_Config_Lmt_FDM_Rawdata_P = <
                900 900
                900 900
                900 900
                900 900
                900 900
                900 900
                900 900
                900 900
                900 900
                900 900
                900 900
                900 900
                900 900
                900 900
                900 900
                900 900
                900 900
                900 900
                900 900
                900 900
                900 900
                900 900
                900 900
                900 900
                900 900
                900 900
                900 900
                900 900
                900 900
                900 900
                900 900
                900 900
                900 900
                900 900
                900 900
                900 900>;

            PS_Config_Lmt_FDM_Rawdata_N = <
                50 50
                50 50
                50 50
                50 50
                50 50
                50 50
                50 50
                50 50
                50 50
                50 50
                50 50
                50 50
                50 50
                50 50
                50 50
                50 50
                50 50
                50 50
                50 50
                50 50
                50 50
                50 50
                50 50
                50 50
                50 50
                50 50
                50 50
                50 50
                50 50
                50 50
                50 50
                50 50
                50 50
                50 50
                50 50
                50 50>;

            PS_Config_FDM_Noise_Test_Frame = <50>;
            PS_Config_Lmt_FDM_Diff_P = <
                180 180
                180 180
                180 180
                180 180
                180 180
                180 180
                180 180
                180 180
                180 180
                180 180
                180 180
                180 180
                180 180
                180 180
                180 180
                180 180
                180 180
                180 180
                180 180
                180 180
                180 180
                180 180
                180 180
                180 180
                180 180
                180 180
                180 180
                180 180
                180 180
                180 180
                180 180
                180 180
                180 180
                180 180
                180 180
                180 180>;

            PS_Config_Lmt_FDM_Diff_N = <
                (-180) (-180)
                (-180) (-180)
                (-180) (-180)
                (-180) (-180)
                (-180) (-180)
                (-180) (-180)
                (-180) (-180)
                (-180) (-180)
                (-180) (-180)
                (-180) (-180)
                (-180) (-180)
                (-180) (-180)
                (-180) (-180)
                (-180) (-180)
                (-180) (-180)
                (-180) (-180)
                (-180) (-180)
                (-180) (-180)
                (-180) (-180)
                (-180) (-180)
                (-180) (-180)
                (-180) (-180)
                (-180) (-180)
                (-180) (-180)
                (-180) (-180)
                (-180) (-180)
                (-180) (-180)
                (-180) (-180)
                (-180) (-180)
                (-180) (-180)
                (-180) (-180)
                (-180) (-180)
                (-180) (-180)
                (-180) (-180)
                (-180) (-180)
                (-180) (-180)>;
        };
    };
    /*Tab A9 code for AX6739W-7 by xiongwei at 20250812 start*/
    jadard@3 {
        compatible = "jadard,jdcommon";
        reg = <3>;
        status = "okay";
        spi-max-frequency = <10000000>;//10M
        interrupt-parent = <&pio>;
        interrupts = <9 0x00>;
        jadard,panel-sense-nums = <22 36>;
        jadard,panel-coords = <0 800 0 1340>;
        jadard,int-is-edge = <1>;
        jadard,panel-max-points = <10>;
        jadard,irq-gpio = <&pio 9 0x00>;
        jadard,rst-gpio = <&pio 155 0x00>;
    };
    /*Tab A9 code for AX6739W-7 by xiongwei at 20250812 end*/
};


/* TOUCH end */
